# STM32F072x register map
Vendor: STM>; File version: 1.0
Registers are 32-bit, read-write, reset 0x0 unless marked. A register's access mark holds for its fields unless they carry their own. Offsets are from the block's base; [hi:lo] are bit positions; {n}, {i} and the like mark numbered series.

## CRS — Clock recovery system
Base 0x40006C00
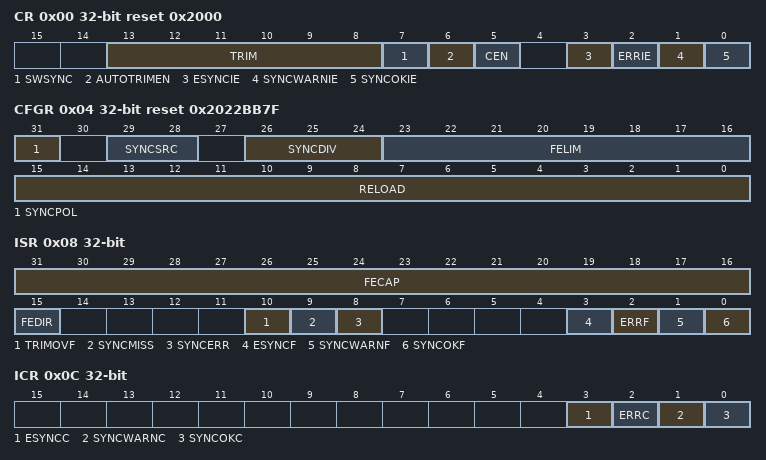
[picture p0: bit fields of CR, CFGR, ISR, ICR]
0x00 CR reset 0x2000 — control register
  [13:8] TRIM — HSI48 oscillator smooth trimming
  [7] SWSYNC — Generate software SYNC event
  [6] AUTOTRIMEN — Automatic trimming enable
  [5] CEN — Frequency error counter enable
  [3] ESYNCIE — Expected SYNC interrupt enable
  [2] ERRIE — Synchronization or trimming error interrupt enable
  [1] SYNCWARNIE — SYNC warning interrupt enable
  [0] SYNCOKIE — SYNC event OK interrupt enable
0x04 CFGR reset 0x2022BB7F — configuration register
  [31] SYNCPOL — SYNC polarity selection
  [29:28] SYNCSRC — SYNC signal source selection
  [26:24] SYNCDIV — SYNC divider
  [23:16] FELIM — Frequency error limit
  [15:0] RELOAD — Counter reload value
0x08 ISR ro — interrupt and status register
  [31:16] FECAP — Frequency error capture
  [15] FEDIR — Frequency error direction
  [10] TRIMOVF — Trimming overflow or underflow
  [9] SYNCMISS — SYNC missed
  [8] SYNCERR — SYNC error
  [3] ESYNCF — Expected SYNC flag
  [2] ERRF — Error flag
  [1] SYNCWARNF — SYNC warning flag
  [0] SYNCOKF — SYNC event OK flag
0x0C ICR — interrupt flag clear register
  [3] ESYNCC — Expected SYNC clear flag
  [2] ERRC — Error clear flag
  [1] SYNCWARNC — SYNC warning clear flag
  [0] SYNCOKC — SYNC event OK clear flag

## CAN — Controller area network
Base 0x40006400
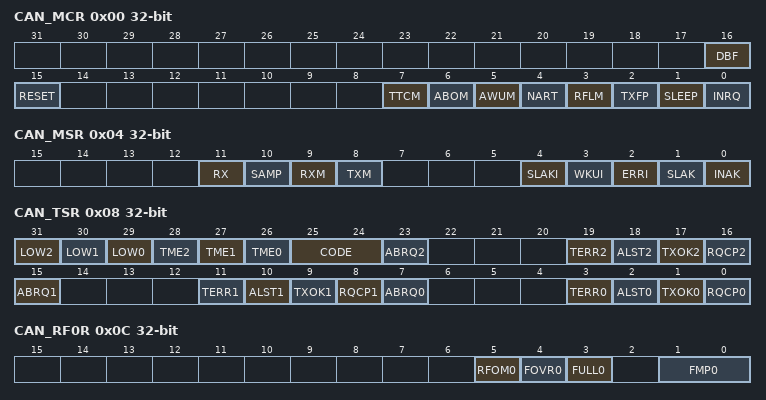
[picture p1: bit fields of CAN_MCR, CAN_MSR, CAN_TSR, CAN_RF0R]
0x00 CAN_MCR
  [16] DBF, [15] RESET, [7] TTCM, [6] ABOM, [5] AWUM, [4] NART, [3] RFLM, [2] TXFP, [1] SLEEP, [0] INRQ
0x04 CAN_MSR access per field
  [11] RX ro, [10] SAMP ro, [9] RXM ro, [8] TXM ro, [4] SLAKI rw, [3] WKUI rw, [2] ERRI rw, [1] SLAK ro, [0] INAK ro
0x08 CAN_TSR access per field
  [31] LOW2 ro — Lowest priority flag for mailbox 2
  [30] LOW1 ro — Lowest priority flag for mailbox 1
  [29] LOW0 ro — Lowest priority flag for mailbox 0
  [28] TME2 ro — Lowest priority flag for mailbox 2
  [27] TME1 ro — Lowest priority flag for mailbox 1
  [26] TME0 ro — Lowest priority flag for mailbox 0
  [25:24] CODE ro
  [23] ABRQ2 rw
  [19] TERR2 rw
  [18] ALST2 rw
  [17] TXOK2 rw
  [16] RQCP2 rw
  [15] ABRQ1 rw
  [11] TERR1 rw
  [10] ALST1 rw
  [9] TXOK1 rw
  [8] RQCP1 rw
  [7] ABRQ0 rw
  [3] TERR0 rw
  [2] ALST0 rw
  [1] TXOK0 rw
  [0] RQCP0 rw
0x0C CAN_RF0R access per field
  [5] RFOM0 rw, [4] FOVR0 rw, [3] FULL0 rw, [1:0] FMP0 ro
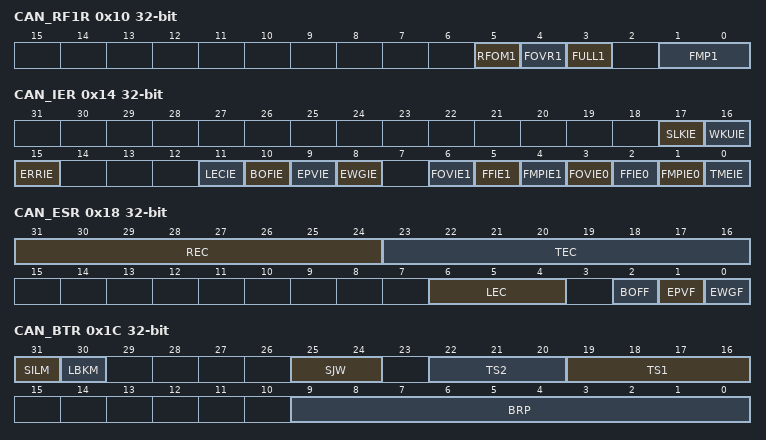
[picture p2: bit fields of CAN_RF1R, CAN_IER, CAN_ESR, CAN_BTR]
0x10 CAN_RF1R access per field
  [5] RFOM1 rw, [4] FOVR1 rw, [3] FULL1 rw, [1:0] FMP1 ro
0x14 CAN_IER
  [17] SLKIE, [16] WKUIE, [15] ERRIE, [11] LECIE, [10] BOFIE, [9] EPVIE, [8] EWGIE, [6] FOVIE1, [5] FFIE1, [4] FMPIE1, [3] FOVIE0, [2] FFIE0, [1] FMPIE0, [0] TMEIE
0x18 CAN_ESR access per field
  [31:24] REC ro, [23:16] TEC ro, [6:4] LEC rw, [2] BOFF ro, [1] EPVF ro, [0] EWGF ro
0x1C CAN_BTR
  [31] SILM, [30] LBKM, [25:24] SJW, [22:20] TS2, [19:16] TS1, [9:0] BRP
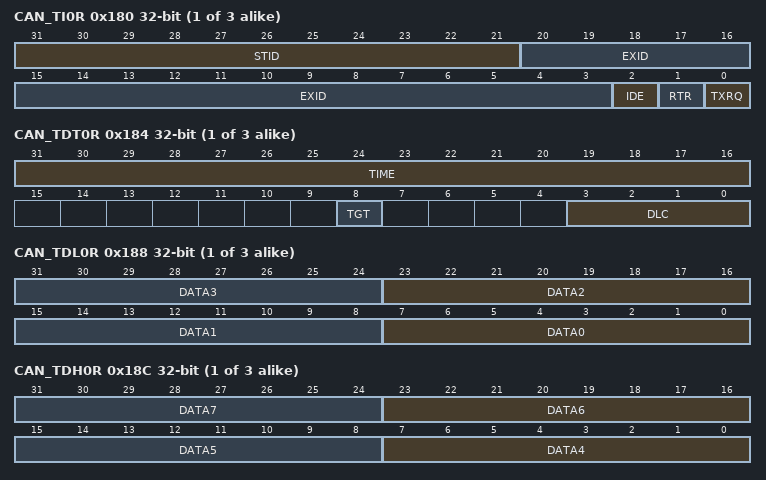
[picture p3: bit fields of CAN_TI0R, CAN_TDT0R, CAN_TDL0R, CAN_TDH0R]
{0x180+0x10*i} CAN_TI{i}R (i=0..2)
  [31:21] STID, [20:3] EXID, [2] IDE, [1] RTR, [0] TXRQ
{0x184+0x10*i} CAN_TDT{i}R (i=0..2)
  [31:16] TIME, [8] TGT, [3:0] DLC
{0x188+0x10*i} CAN_TDL{i}R (i=0..2)
  [8n+7:8n] DATA{n} (n=0..3)
{0x18C+0x10*i} CAN_TDH{i}R (i=0..2)
  [8n-25:8n-32] DATA{n} (n=4..7)
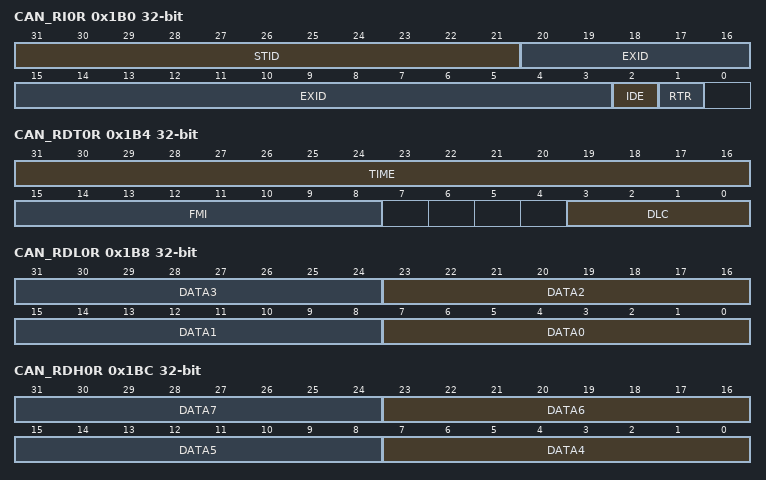
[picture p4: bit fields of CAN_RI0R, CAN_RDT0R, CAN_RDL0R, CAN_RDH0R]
0x1B0 CAN_RI0R ro
  [31:21] STID, [20:3] EXID, [2] IDE, [1] RTR
0x1B4 CAN_RDT0R ro
  [31:16] TIME, [15:8] FMI, [3:0] DLC
0x1B8 CAN_RDL0R ro
  [8n+7:8n] DATA{n} (n=0..3)
0x1BC CAN_RDH0R ro
  [8n-25:8n-32] DATA{n} (n=4..7)
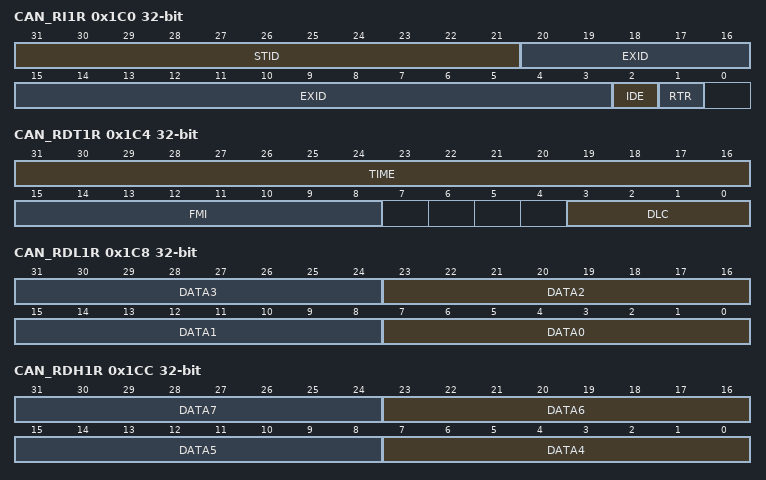
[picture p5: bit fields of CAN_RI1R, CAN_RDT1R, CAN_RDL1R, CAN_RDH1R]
0x1C0 CAN_RI1R ro
  [31:21] STID, [20:3] EXID, [2] IDE, [1] RTR
0x1C4 CAN_RDT1R ro
  [31:16] TIME, [15:8] FMI, [3:0] DLC
0x1C8 CAN_RDL1R ro
  [8n+7:8n] DATA{n} (n=0..3)
0x1CC CAN_RDH1R ro
  [8n-25:8n-32] DATA{n} (n=4..7)
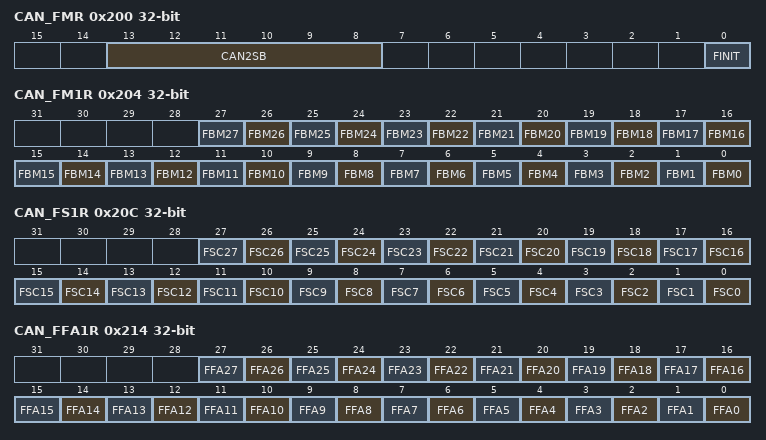
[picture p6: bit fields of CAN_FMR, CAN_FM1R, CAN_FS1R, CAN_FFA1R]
0x200 CAN_FMR
  [13:8] CAN2SB, [0] FINIT
0x204 CAN_FM1R
  [n] FBM{n} (n=0..27) — Filter mode
0x20C CAN_FS1R
  [n] FSC{n} (n=0..27) — Filter scale configuration
0x214 CAN_FFA1R
  [n] FFA{n} (n=0..27) — Filter FIFO assignment for filter {n}
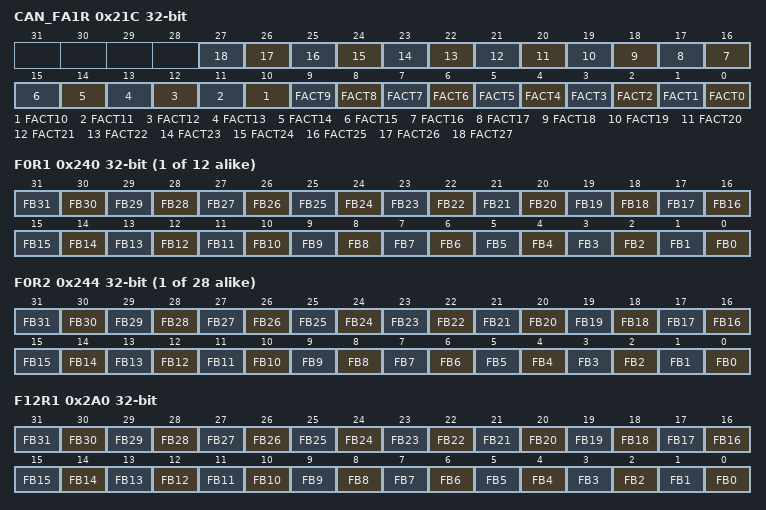
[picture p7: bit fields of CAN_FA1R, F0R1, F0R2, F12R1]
0x21C CAN_FA1R
  [n] FACT{n} (n=0..27) — Filter active
{0x240+8i} F{i}R1 (i=0..11) — Filter bank {i} register 1
  [n] FB{n} (n=0..31) — Filter bits
{0x244+8i} F{i}R2 (i=0..27) — Filter bank {i} register 2
  [n] FB{n} (n=0..31) — Filter bits
0x2A0 F12R1 — Filter bank 4 register 1
  [n] FB{n} (n=0..31) — Filter bits
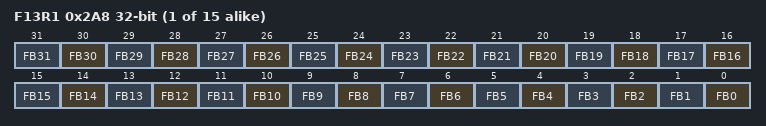
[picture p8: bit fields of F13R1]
{0x240+8i} F{i}R1 (i=13..27) — Filter bank {i} register 1
  [n] FB{n} (n=0..31) — Filter bits
